VERSION ""

NS_ :

BS_:

BU_: MCU_B_R EOP_R

BO_ 1731 DiagPhysReqToEOP_FVT_R: 8 MCU_B_R
 SG_ DiagPhysReqToEOP_FVT_R : 7|64@0+ (1,0) [0|0] "" EOP_R

BO_ 1603 DiagRespFromEOP_FVT_R: 8 EOP_R
 SG_ DiagRespFromEOP_FVT_R : 7|64@0+ (1,0) [0|0] "" MCU_B_R

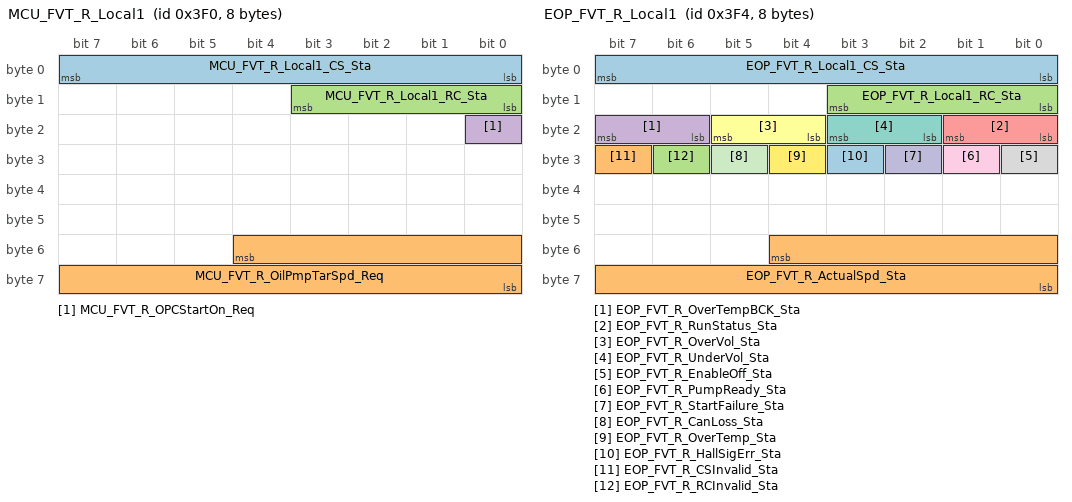
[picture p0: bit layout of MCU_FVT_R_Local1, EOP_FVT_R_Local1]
BO_ 1008 MCU_FVT_R_Local1: 8 MCU_B_R
 SG_ MCU_FVT_R_Local1_CS_Sta : 7|8@0+ (1,0) [0|255] "" EOP_R
 SG_ MCU_FVT_R_OilPmpTarSpd_Req : 52|13@0+ (1,0) [0|8191] "RPM" EOP_R
 SG_ MCU_FVT_R_Local1_RC_Sta : 11|4@0+ (1,0) [0|14] "" EOP_R
 SG_ MCU_FVT_R_OPCStartOn_Req : 16|1@0+ (1,0) [0|1] "" EOP_R

BO_ 1012 EOP_FVT_R_Local1: 8 EOP_R
 SG_ EOP_FVT_R_Local1_CS_Sta : 7|8@0+ (1,0) [0|255] "" MCU_B_R
 SG_ EOP_FVT_R_ActualSpd_Sta : 52|13@0+ (1,0) [0|8191] "RPM" MCU_B_R
 SG_ EOP_FVT_R_Local1_RC_Sta : 11|4@0+ (1,0) [0|14] "" MCU_B_R
 SG_ EOP_FVT_R_OverTempBCK_Sta : 23|2@0+ (1,0) [0|3] "" MCU_B_R
 SG_ EOP_FVT_R_RunStatus_Sta : 17|2@0+ (1,0) [0|3] "" MCU_B_R
 SG_ EOP_FVT_R_OverVol_Sta : 21|2@0+ (1,0) [0|3] "" MCU_B_R
 SG_ EOP_FVT_R_UnderVol_Sta : 19|2@0+ (1,0) [0|3] "" MCU_B_R
 SG_ EOP_FVT_R_EnableOff_Sta : 24|1@0+ (1,0) [0|1] "" MCU_B_R
 SG_ EOP_FVT_R_PumpReady_Sta : 25|1@0+ (1,0) [0|1] "" MCU_B_R
 SG_ EOP_FVT_R_StartFailure_Sta : 26|1@0+ (1,0) [0|1] "" MCU_B_R
 SG_ EOP_FVT_R_CanLoss_Sta : 29|1@0+ (1,0) [0|1] "" MCU_B_R
 SG_ EOP_FVT_R_OverTemp_Sta : 28|1@0+ (1,0) [0|1] "" MCU_B_R
 SG_ EOP_FVT_R_HallSigErr_Sta : 27|1@0+ (1,0) [0|1] "" MCU_B_R
 SG_ EOP_FVT_R_CSInvalid_Sta : 31|1@0+ (1,0) [0|1] "" MCU_B_R
 SG_ EOP_FVT_R_RCInvalid_Sta : 30|1@0+ (1,0) [0|1] "" MCU_B_R

CM_ SG_ 1731 DiagPhysReqToEOP_FVT_R "Diagnostic Physical Request to EOP_FVT_R";
CM_ SG_ 1603 DiagRespFromEOP_FVT_R "Diagnostic Response from EOP_FVT_R";
CM_ SG_ 1008 MCU_FVT_R_Local1_CS_Sta "Checksum of MCU_FVT_R_Local1 (AUTOSAR E2E profile 1)
Polynomial 0x1D (x^8+x^4+x^3+x^2+1) Both start value and XOR value are 0x00.
";
CM_ SG_ 1008 MCU_FVT_R_OilPmpTarSpd_Req "EOP Target Speed Request";
CM_ SG_ 1008 MCU_FVT_R_Local1_RC_Sta "MCU_FVT_R_Local1 4-bit rolling counter
It starts counting from 0, ends at 14 and returns to zero (0~14).";
CM_ SG_ 1008 MCU_FVT_R_OPCStartOn_Req "Motor running request ";
CM_ SG_ 1012 EOP_FVT_R_Local1_CS_Sta "Checksum of EOP_FVT_R_Local1 (AUTOSAR E2E profile 1)
Polynomial 0x1D (x^8+x^4+x^3+x^2+1) Both start value and XOR value are 0x00.
";
CM_ SG_ 1012 EOP_FVT_R_ActualSpd_Sta "EOP Actual speed";
CM_ SG_ 1012 EOP_FVT_R_Local1_RC_Sta "EOP_FVT_R_Local1 4-bit rolling counter
It starts counting from 0, ends at 14 and returns to zero (0~14).";
CM_ SG_ 1012 EOP_FVT_R_OverTempBCK_Sta "EOP OverTemperature range status";
CM_ SG_ 1012 EOP_FVT_R_RunStatus_Sta "EOP system operation mode";
CM_ SG_ 1012 EOP_FVT_R_OverVol_Sta "EOP Over Voltage status";
CM_ SG_ 1012 EOP_FVT_R_UnderVol_Sta "EOP Under Voltage status";
CM_ SG_ 1012 EOP_FVT_R_EnableOff_Sta "Motor run Status
0: Motor run (opcstart = 1 and oilpmptargetspeed > 0)
1: Motor stop (opcstart = 0 or oilmptargetspeed = 0)";
CM_ SG_ 1012 EOP_FVT_R_PumpReady_Sta "Motor Ready status
0: The system self-check failed
1: The system self-check is successful";
CM_ SG_ 1012 EOP_FVT_R_StartFailure_Sta "Motor block status";
CM_ SG_ 1012 EOP_FVT_R_CanLoss_Sta "EOP has not received CAN messages from MCU for 2 seconds, reporting a CAN loss fault.";
CM_ SG_ 1012 EOP_FVT_R_OverTemp_Sta "EOP OverTemperature status";
CM_ SG_ 1012 EOP_FVT_R_HallSigErr_Sta "EOP Hall Signal Error status";
CM_ SG_ 1012 EOP_FVT_R_CSInvalid_Sta "MCU CheckSum Invalid status";
CM_ SG_ 1012 EOP_FVT_R_RCInvalid_Sta "MCU Rolling Counter Invalid status";

BA_DEF_ "NmType" STRING ;
BA_DEF_ "VersionYear" INT 2010 2999;
BA_DEF_ "ProtocolType" STRING ;
BA_DEF_ "NmMessageCount" INT 0 255;
BA_DEF_ "NmBaseAddress" HEX 1280 1407;
BA_DEF_ "DBName" STRING ;
BA_DEF_ "BusType" STRING ;
BA_DEF_ "Baudrate" INT 0 1000000;
BA_DEF_ "Datarate" INT 0 2000000;
BA_DEF_ BO_ "GenMsgSendType" ENUM "Cycle","NoMsgSendType","IfActive","Event","CA","CE";
BA_DEF_ BO_ "GenMsgILSupport" ENUM "No","Yes";
BA_DEF_ BO_ "GenMsgCycleTime" INT 0 0;
BA_DEF_ BO_ "DiagResponse" ENUM "No","Yes";
BA_DEF_ BO_ "DiagRequest" ENUM "No","Yes";
BA_DEF_ BO_ "VFrameFormat" ENUM "StandardCAN","ExtendedCAN","StandardCAN_FD","ExtendedCAN_FD","reserved","J1939PG";
BA_DEF_ BO_ "DataID" STRING ;
BA_DEF_ BO_ "DoIPLogicalAddress" STRING ;
BA_DEF_ BO_ "CANFD_BRS" ENUM "0","1";
BA_DEF_ BO_ "GenMsgRequestable" INT 0 1;
BA_DEF_ BU_ "NodeLayerModules" STRING ;
BA_DEF_ BU_ "ILUsed" ENUM "No","Yes";
BA_DEF_ BU_ "NmCAN" INT 1 2;
BA_DEF_ BU_ "CAN_CANFD_Gateway" ENUM "Yes","No";
BA_DEF_ BU_ "BootloaderNode" ENUM "No","Yes";
BA_DEF_ SG_ "GenSigInvalidValue" HEX 0 0;
BA_DEF_ SG_ "GenSigRoutingTimeoutValue_String" STRING ;
BA_DEF_ SG_ "GenSigRoutingTimeoutValue" HEX 0 0;
BA_DEF_ SG_ "GenSigSendType" ENUM "Cycle","OnWrite","OnWriteWithRepetition","OnChange","OnChangeWithRepetition","IfActive","IfActiveWithRepetition","NoSigSendType","vector_leerstring";
BA_DEF_ SG_ "SigType" ENUM "Default","Range","RangeSigned","ASCII","Discrete","Control","ReferencePGN","DTC","StringDelimiter","StringLength","StringLengthControl","MessageCounter","MessageChecksum";
BA_DEF_ SG_ "GenSigILSupport" ENUM "No","Yes";
BA_DEF_DEF_ "NmType" "AUTOSAR";
BA_DEF_DEF_ "VersionYear" 2024;
BA_DEF_DEF_ "ProtocolType" "CAN";
BA_DEF_DEF_ "NmMessageCount" 128;
BA_DEF_DEF_ "NmBaseAddress" 1280;
BA_DEF_DEF_ "DBName" "";
BA_DEF_DEF_ "BusType" "CAN";
BA_DEF_DEF_ "Baudrate" 500000;
BA_DEF_DEF_ "Datarate" 2000000;
BA_DEF_DEF_ "GenMsgSendType" "Cycle";
BA_DEF_DEF_ "GenMsgILSupport" "Yes";
BA_DEF_DEF_ "GenMsgCycleTime" 100;
BA_DEF_DEF_ "DiagResponse" "No";
BA_DEF_DEF_ "DiagRequest" "No";
BA_DEF_DEF_ "VFrameFormat" "StandardCAN";
BA_DEF_DEF_ "DataID" "";
BA_DEF_DEF_ "DoIPLogicalAddress" "";
BA_DEF_DEF_ "CANFD_BRS" "1";
BA_DEF_DEF_ "GenMsgRequestable" 1;
BA_DEF_DEF_ "NodeLayerModules" "CANoeILNLVector.dll";
BA_DEF_DEF_ "ILUsed" "Yes";
BA_DEF_DEF_ "NmCAN" 2;
BA_DEF_DEF_ "CAN_CANFD_Gateway" "No";
BA_DEF_DEF_ "BootloaderNode" "No";
BA_DEF_DEF_ "GenSigInvalidValue" 0;
BA_DEF_DEF_ "GenSigRoutingTimeoutValue_String" "";
BA_DEF_DEF_ "GenSigRoutingTimeoutValue" 0;
BA_DEF_DEF_ "GenSigSendType" "Cycle";
BA_DEF_DEF_ "SigType" "Default";
BA_DEF_DEF_ "GenSigILSupport" "Yes";
BA_ "DBName" "CAN_MCU_R1";
BA_ "BootloaderNode" BU_ MCU_B_R 1;
BA_ "CAN_CANFD_Gateway" BU_ MCU_B_R 0;
BA_ "BootloaderNode" BU_ EOP_R 1;
BA_ "GenMsgCycleTime" BO_ 1731 0;
BA_ "DiagRequest" BO_ 1731 1;
BA_ "GenMsgSendType" BO_ 1731 3;
BA_ "DoIPLogicalAddress" BO_ 1731 "0x06C3";
BA_ "GenMsgCycleTime" BO_ 1603 0;
BA_ "DiagResponse" BO_ 1603 1;
BA_ "GenMsgSendType" BO_ 1603 3;
BA_ "DoIPLogicalAddress" BO_ 1603 "0x06C3";
BA_ "GenMsgCycleTime" BO_ 1008 10;
BA_ "DataID" BO_ 1008 "0x30F8";
BA_ "GenMsgCycleTime" BO_ 1012 10;
BA_ "DataID" BO_ 1012 "0xF458";
BA_ "GenSigSendType" SG_ 1731 DiagPhysReqToEOP_FVT_R 3;
BA_ "GenSigSendType" SG_ 1603 DiagRespFromEOP_FVT_R 3;
BA_ "GenSigInvalidValue" SG_ 1008 MCU_FVT_R_OilPmpTarSpd_Req 8191;
BA_ "GenSigRoutingTimeoutValue_String" SG_ 1008 MCU_FVT_R_OilPmpTarSpd_Req "0x1FFF";
BA_ "GenSigRoutingTimeoutValue" SG_ 1008 MCU_FVT_R_OilPmpTarSpd_Req 8191;
BA_ "GenSigRoutingTimeoutValue_String" SG_ 1008 MCU_FVT_R_OPCStartOn_Req "0x0";
BA_ "GenSigInvalidValue" SG_ 1012 EOP_FVT_R_ActualSpd_Sta 8191;
BA_ "GenSigRoutingTimeoutValue_String" SG_ 1012 EOP_FVT_R_ActualSpd_Sta "0x1FFF";
BA_ "GenSigRoutingTimeoutValue" SG_ 1012 EOP_FVT_R_ActualSpd_Sta 8191;
VAL_ 1008 MCU_FVT_R_OilPmpTarSpd_Req 8191 "Invalid";
VAL_ 1008 MCU_FVT_R_OPCStartOn_Req 1 "StartOn" 0 "Off";
VAL_ 1012 EOP_FVT_R_ActualSpd_Sta 8191 "Invalid";
VAL_ 1012 EOP_FVT_R_OverTempBCK_Sta 2 "Over temperature" 1 "High temperature" 0 "Normal temperature";
VAL_ 1012 EOP_FVT_R_RunStatus_Sta 3 "Failure mode" 2 "Derating operation mode" 1 "Motor operation mode" 0 "Speed mode";
VAL_ 1012 EOP_FVT_R_OverVol_Sta 3 "Battery and V_HD over voltage" 2 "Battery over voltage" 1 "V_HD over voltage" 0 "Normal";
VAL_ 1012 EOP_FVT_R_UnderVol_Sta 3 "GDU and Battery under voltage" 2 "Battery under voltage" 1 "GDU under voltage" 0 "Normal";
VAL_ 1012 EOP_FVT_R_EnableOff_Sta 1 "Motor stop" 0 "Motor run";
VAL_ 1012 EOP_FVT_R_PumpReady_Sta 1 "The system self-check is successful" 0 "The system self-check failed";
VAL_ 1012 EOP_FVT_R_StartFailure_Sta 1 "Motor block" 0 "No Motor block";
VAL_ 1012 EOP_FVT_R_CanLoss_Sta 1 "CanNodeLoss" 0 "No fault";
VAL_ 1012 EOP_FVT_R_OverTemp_Sta 1 "Over temperature" 0 "No fault";
VAL_ 1012 EOP_FVT_R_HallSigErr_Sta 1 "Error" 0 "Normal";
VAL_ 1012 EOP_FVT_R_CSInvalid_Sta 1 "Error" 0 "Normal";
VAL_ 1012 EOP_FVT_R_RCInvalid_Sta 1 "Error" 0 "Normal";
